# ATtiny1614 register map
Vendor: Atmel; File version: 1.0
CPU: other r0p0, little endian, no MPU, no FPU, 4 interrupt priority bits
Registers are 8-bit, read-write, reset 0x0 unless marked. A register's access mark holds for its fields unless they carry their own. Offsets are from the block's base; [hi:lo] are bit positions; {n}, {i} and the like mark numbered series.

## PORTMUX — Port Multiplexer
Base 0x00800200
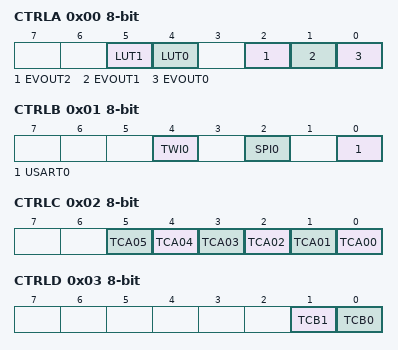
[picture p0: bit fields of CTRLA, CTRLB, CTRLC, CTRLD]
0x00 CTRLA — Port Multiplexer Control A
  [5] LUT1 — Configurable Custom Logic LUT1
    0=DEFAULT (Default pin); 1=ALTERNATE (Alternate pin)
  [4] LUT0 — Configurable Custom Logic LUT0
    0=DEFAULT (Default pin); 1=ALTERNATE (Alternate pin)
  [2] EVOUT2 — Event Output 2
  [1] EVOUT1 — Event Output 1
  [0] EVOUT0 — Event Output 0
0x01 CTRLB — Port Multiplexer Control B
  [all] fields
    0=DEFAULT (Default pins); 1=ALTERNATE (Alternate pins)
  [4] TWI0 — Port Multiplexer TWI0
  [2] SPI0 — Port Multiplexer SPI0
  [0] USART0 — Port Multiplexer USART0
0x02 CTRLC — Port Multiplexer Control C
  [all] fields
    0=DEFAULT (Default pin); 1=ALTERNATE (Alternate pin)
  [n] TCA{n:02} (n=0..5) — Port Multiplexer TCA0 Output {n}
0x03 CTRLD — Port Multiplexer Control D
  [1] TCB1 — Port Multiplexer TCB1
    0=DEFAULT (Default pin); 1=ALTERNATE (Alternate pin)
  [0] TCB0 — Port Multiplexer TCB0
    0=DEFAULT (Default pin); 1=ALTERNATE (Alternate pin)

## RSTCTRL — Reset controller
Base 0x00800040
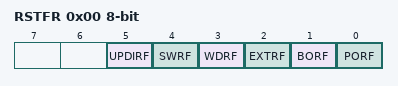
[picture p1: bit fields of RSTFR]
0x00 RSTFR — Reset Flags
  [5] UPDIRF — UPDI Reset flag
  [4] SWRF — Software Reset flag
  [3] WDRF — Watch dog Reset flag
  [2] EXTRF — External Reset flag
  [1] BORF — Brown out detector Reset flag
  [0] PORF — Power on Reset flag
0x01 SWRR — Software Reset
  [0] SWRE — Software reset enable

## RTC — Real-Time Counter
Base 0x00800140
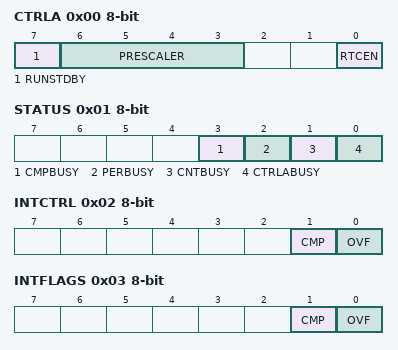
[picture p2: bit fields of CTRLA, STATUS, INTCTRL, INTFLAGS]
0x00 CTRLA — Control A
  [7] RUNSTDBY — Run In Standby
  [6:3] PRESCALER — Prescaling Factor
    0=DIV1 (RTC Clock / 1); 1=DIV2 (RTC Clock / 2); 2=DIV4 (RTC Clock / 4); 3=DIV8 (RTC Clock / 8); 4=DIV16 (RTC Clock / 16); 5=DIV32 (RTC Clock / 32); 6=DIV64 (RTC Clock / 64); 7=DIV128 (RTC Clock / 128); 8=DIV256 (RTC Clock / 256); 9=DIV512 (RTC Clock / 512); 10=DIV1024 (RTC Clock / 1024); 11=DIV2048 (RTC Clock / 2048); 12=DIV4096 (RTC Clock / 4096); 13=DIV8192 (RTC Clock / 8192); 14=DIV16384 (RTC Clock / 16384); 15=DIV32768 (RTC Clock / 32768)
  [0] RTCEN — Enable
0x01 STATUS ro
  [3] CMPBUSY — Comparator Synchronization Busy Flag
  [2] PERBUSY — Period Synchronization Busy Flag
  [1] CNTBUSY — Count Synchronization Busy Flag
  [0] CTRLABUSY — CTRLA Synchronization Busy Flag
0x02 INTCTRL — Interrupt Control
  [1] CMP — Compare Match Interrupt enable
  [0] OVF — Overflow Interrupt enable
0x03 INTFLAGS — Interrupt Flags
  [1] CMP — Compare Match Interrupt
  [0] OVF — Overflow Interrupt Flag
0x04 TEMP — Temporary
0x05 DBGCTRL — Debug control
  [0] DBGRUN — Run in debug
0x07 CLKSEL — Clock Select
  [1:0] CLKSEL
    0=INT32K (Internal 32kHz OSC); 1=INT1K (Internal 1kHz OSC); 2=TOSC32K (32KHz Crystal OSC); 3=EXTCLK (External Clock)
0x08 CNT 16-bit (reset mask 0xFF) — Counter
0x0A PER 16-bit (reset mask 0xFF) — Period
0x0C CMP 16-bit (reset mask 0xFF) — Compare
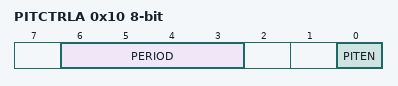
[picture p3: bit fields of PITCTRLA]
0x10 PITCTRLA — PIT Control A
  [6:3] PERIOD
    0=OFF; 1=CYC4 (RTC Clock Cycles 4); 2=CYC8 (RTC Clock Cycles 8); 3=CYC16 (RTC Clock Cycles 16); 4=CYC32 (RTC Clock Cycles 32); 5=CYC64 (RTC Clock Cycles 64); 6=CYC128 (RTC Clock Cycles 128); 7=CYC256 (RTC Clock Cycles 256); 8=CYC512 (RTC Clock Cycles 512); 9=CYC1024 (RTC Clock Cycles 1024); 10=CYC2048 (RTC Clock Cycles 2048); 11=CYC4096 (RTC Clock Cycles 4096); 12=CYC8192 (RTC Clock Cycles 8192); 13=CYC16384 (RTC Clock Cycles 16384); 14=CYC32768 (RTC Clock Cycles 32768)
  [0] PITEN — Enable
0x11 PITSTATUS ro
  [0] CTRLBUSY — CTRLA Synchronization Busy Flag
0x12 PITINTCTRL — PIT Interrupt Control
  [0] PI — Periodic Interrupt
0x13 PITINTFLAGS — PIT Interrupt Flags
  [0] PI — Periodic Interrupt
0x15 PITDBGCTRL — PIT Debug control
  [0] DBGRUN — Run in debug

## SIGROW — Signature row
Base 0x00801100
{0x0+i} DEVICEID{i} ro (i=0..2) — Device ID Byte {i}
{0x3+i} SERNUM{i} ro (i=0..9) — Serial Number Byte {i}
0x20 TEMPSENSE0 ro — Temperature Sensor Calibration Byte 0
0x21 TEMPSENSE1 ro — Temperature Sensor Calibration Byte 1
0x22 OSC16ERR3V ro — OSC16 error at 3V
0x23 OSC16ERR5V ro — OSC16 error at 5V
0x24 OSC20ERR3V ro — OSC20 error at 3V
0x25 OSC20ERR5V ro — OSC20 error at 5V
